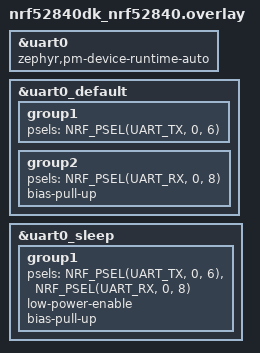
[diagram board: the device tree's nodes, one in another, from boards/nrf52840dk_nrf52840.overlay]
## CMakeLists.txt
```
#
# Copyright (c) 2018 Nordic Semiconductor
#
# SPDX-License-Identifier: LicenseRef-Nordic-5-Clause
#
cmake_minimum_required(VERSION 3.20.0)

# Add configs
list(APPEND EXTRA_CONF_FILE
  "${CMAKE_CURRENT_LIST_DIR}/src/mpsl_esb/mpsl-esb-overlay.conf"
)

set(EXTRA_CONF_FILE ${EXTRA_CONF_FILE} CACHE INTERNAL "")

find_package(Zephyr REQUIRED HINTS $ENV{ZEPHYR_BASE})
project(ble_esb_low_power)

# NORDIC SDK APP START
target_sources(app PRIVATE
  src/main.c
)

add_subdirectory(src/mpsl_esb)

# NORDIC SDK APP END
```

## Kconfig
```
#
# Copyright (c) 2018 Nordic Semiconductor
#
# SPDX-License-Identifier: LicenseRef-Nordic-5-Clause
#

rsource "src/mpsl_esb/Kconfig.mpsl_esb"

source "Kconfig.zephyr"

menu "Nordic LED-Button BLE GATT service sample"

config BT_LBS_SECURITY_ENABLED
	bool "Enable security"
	default y
	select BT_SMP
	select BT_SETTINGS
	select FLASH
	select FLASH_PAGE_LAYOUT
	select FLASH_MAP
	select ZMS if (SOC_FLASH_NRF_RRAM || SOC_FLASH_NRF_MRAM)
	select NVS if !(SOC_FLASH_NRF_RRAM || SOC_FLASH_NRF_MRAM)
	select SETTINGS
	help
	  "Enable BLE security for the LED-Button service"

endmenu
```

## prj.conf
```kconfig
#
# Copyright (c) 2018 Nordic Semiconductor
#
# SPDX-License-Identifier: LicenseRef-Nordic-5-Clause
#
CONFIG_NCS_SAMPLES_DEFAULTS=y

CONFIG_BT=y
CONFIG_BT_PERIPHERAL=y
CONFIG_BT_DEVICE_NAME="Nordic_LBS"

# Enable the LBS service
CONFIG_BT_LBS=y
CONFIG_BT_LBS_POLL_BUTTON=y
CONFIG_DK_LIBRARY=y

CONFIG_BT_MAX_CONN=2

CONFIG_SYSTEM_WORKQUEUE_STACK_SIZE=2048

# ESB
CONFIG_ESB_CLOCK_INIT=n



# CONFIG_DEBUG=y
# CONFIG_THREAD_ANALYZER=y
# CONFIG_THREAD_MONITOR=y
# CONFIG_THREAD_NAME=y
# CONFIG_THREAD_STACK_INFO=y
# CONFIG_THREAD_RUNTIME_STATS=y

# enable logging, set UART as backend
CONFIG_LOG=y
CONFIG_CONSOLE=y
CONFIG_LOG_MODE_DEFERRED=y
CONFIG_LOG_BACKEND_UART=y
CONFIG_PRINTK=y
CONFIG_UART_CONSOLE=y
CONFIG_LOG_PRINTK=y
CONFIG_USE_SEGGER_RTT=n
CONFIG_RTT_CONSOLE=n

# enable async uart for the log backend
CONFIG_LOG_BACKEND_UART_ASYNC=y
CONFIG_UART_ASYNC_API=y


# The hardware counter is only used for RX
# we don't need to use it for logging
# CONFIG_UART_0_NRF_HW_ASYNC=y
# CONFIG_UART_0_NRF_HW_ASYNC_TIMER=1
# CONFIG_NRFX_TIMER1=y


# disable all uart input features
CONFIG_SHELL=n
CONFIG_CONSOLE_HANDLER=n


# Low power for Zephyr Device Drivers
CONFIG_PM_DEVICE_RUNTIME=y
CONFIG_PM_DEVICE=y
```

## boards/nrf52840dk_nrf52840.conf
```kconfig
CONFIG_UART_0_INTERRUPT_DRIVEN=n
CONFIG_UART_0_ASYNC=y
```

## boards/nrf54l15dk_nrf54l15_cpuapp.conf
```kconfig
# nRF54L15: console UART is uart20 (not uart0)
CONFIG_UART_20_INTERRUPT_DRIVEN=n
CONFIG_UART_20_ASYNC=y
```

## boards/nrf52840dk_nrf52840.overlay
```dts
&uart0 {
    status = "okay";
    zephyr,pm-device-runtime-auto;
    /delete-property/ hw-flow-control;
};

&uart0_default {
    group1 {
        psels = <NRF_PSEL(UART_TX, 0, 6)>;
    };
    group2 {
        psels = <NRF_PSEL(UART_RX, 0, 8)>;
        bias-pull-up;
    };
};

&uart0_sleep {
    group1 {
        psels = <NRF_PSEL(UART_TX, 0, 6)>,
            <NRF_PSEL(UART_RX, 0, 8)>;
        low-power-enable;
        bias-pull-up;
    };
};
```

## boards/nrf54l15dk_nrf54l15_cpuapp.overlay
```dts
/* nRF54L15DK: console is on uart20 (TX=P1.4, RX=P1.5) */
&uart20 {
    status = "okay";
    zephyr,pm-device-runtime-auto;
    /delete-property/ hw-flow-control;
};

/* Remove RTS/CTS pins from the default pinctrl group */
&uart20_default {
    group1 {
        psels = <NRF_PSEL(UART_TX, 1, 4)>;
    };
    group2 {
        psels = <NRF_PSEL(UART_RX, 1, 5)>;
        bias-pull-up;
    };
};

&uart20_sleep {
    group1 {
        psels = <NRF_PSEL(UART_TX, 1, 4)>,
            <NRF_PSEL(UART_RX, 1, 5)>;
        low-power-enable;
        bias-pull-up;
    };
};
```

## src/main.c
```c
/*
 * Copyright (c) 2018 Nordic Semiconductor ASA
 *
 * SPDX-License-Identifier: LicenseRef-Nordic-5-Clause
 */

#include <zephyr/types.h>
#include <stddef.h>
#include <string.h>
#include <errno.h>
#include <zephyr/sys/printk.h>
#include <zephyr/sys/byteorder.h>
#include <zephyr/kernel.h>
#include <zephyr/drivers/gpio.h>
#include <soc.h>

#include <zephyr/bluetooth/bluetooth.h>
#include <zephyr/bluetooth/hci.h>
#include <zephyr/bluetooth/conn.h>
#include <zephyr/bluetooth/uuid.h>
#include <zephyr/bluetooth/gatt.h>

#include <bluetooth/services/lbs.h>

#include <zephyr/settings/settings.h>

#include <dk_buttons_and_leds.h>

#define DEVICE_NAME             CONFIG_BT_DEVICE_NAME
#define DEVICE_NAME_LEN         (sizeof(DEVICE_NAME) - 1)


#define RUN_STATUS_LED          DK_LED1
#define CON_STATUS_LED          DK_LED2
#define RUN_LED_BLINK_INTERVAL  1000

#define USER_LED                DK_LED3

#define USER_BUTTON             DK_BTN1_MSK

static bool app_button_state;

static const struct bt_data ad[] = {
	BT_DATA_BYTES(BT_DATA_FLAGS, (BT_LE_AD_GENERAL | BT_LE_AD_NO_BREDR)),
	BT_DATA(BT_DATA_NAME_COMPLETE, DEVICE_NAME, DEVICE_NAME_LEN),
};

static const struct bt_data sd[] = {
	BT_DATA_BYTES(BT_DATA_UUID128_ALL, BT_UUID_LBS_VAL),
};

static void connected(struct bt_conn *conn, uint8_t err)
{
	if (err) {
		printk("Connection failed, err 0x%02x %s\n", err, bt_hci_err_to_str(err));
		return;
	}

	printk("Connected\n");

	dk_set_led_on(CON_STATUS_LED);

	struct bt_le_conn_param param = {
		.interval_min = 400, // 400 * 1.25 ms = 500 ms
		.interval_max = 400, // 400 * 1.25 ms = 500 ms
		.latency = 0,       
		.timeout = 200,     // 200*10ms = 2s
        /**
         * Bluetooth requries:
         *   Timeout_ms > 2 * (1 + latency_ms) * interval_max_ms
         * 
		 * variable style:
         *   timeout * 4 > (1 + latency) * interval_max
         */
        /**
         * iOS Requriements:
         *   - Interval Min ≥ 15 ms (multiples of 15 ms)
         *   - Interval Min + 15 ms ≤ Interval Max (Interval Max == 15 ms is allowed)
         *   - Interval Max * (Slave Latency + 1) ≤ 2 seconds
         *   - Interval Max * (Slave Latency + 1) * 3 < connSupervisionTimeout
         *   - Slave Latency ≤ 30
         *   - 2 seconds ≤ connSupervisionTimeout ≤ 6 seconds
         */

	};

	int ret = bt_conn_le_param_update(conn, &param);

	if (ret == -EALREADY) {
        printk("Connection parameters are already set.");
		ret = 0;
	}
    
    if (ret) {
        printk("Failed to update connection parameters (ret %d)", ret);
    }
}

static void disconnected(struct bt_conn *conn, uint8_t reason)
{
	printk("Disconnected, reason 0x%02x %s\n", reason, bt_hci_err_to_str(reason));

	dk_set_led_off(CON_STATUS_LED);
}

#ifdef CONFIG_BT_LBS_SECURITY_ENABLED
static void security_changed(struct bt_conn *conn, bt_security_t level,
			     enum bt_security_err err)
{
	char addr[BT_ADDR_LE_STR_LEN];

	bt_addr_le_to_str(bt_conn_get_dst(conn), addr, sizeof(addr));

	if (!err) {
		printk("Security changed: %s level %u\n", addr, level);
	} else {
		printk("Security failed: %s level %u err %d %s\n", addr, level, err,
		       bt_security_err_to_str(err));
	}
}
#endif

BT_CONN_CB_DEFINE(conn_callbacks) = {
	.connected        = connected,
	.disconnected     = disconnected,
#ifdef CONFIG_BT_LBS_SECURITY_ENABLED
	.security_changed = security_changed,
#endif
};

#if defined(CONFIG_BT_LBS_SECURITY_ENABLED)
static void auth_passkey_display(struct bt_conn *conn, unsigned int passkey)
{
	char addr[BT_ADDR_LE_STR_LEN];

	bt_addr_le_to_str(bt_conn_get_dst(conn), addr, sizeof(addr));

	printk("Passkey for %s: %06u\n", addr, passkey);
}

static void auth_cancel(struct bt_conn *conn)
{
	char addr[BT_ADDR_LE_STR_LEN];

	bt_addr_le_to_str(bt_conn_get_dst(conn), addr, sizeof(addr));

	printk("Pairing cancelled: %s\n", addr);
}

static void pairing_complete(struct bt_conn *conn, bool bonded)
{
	char addr[BT_ADDR_LE_STR_LEN];

	bt_addr_le_to_str(bt_conn_get_dst(conn), addr, sizeof(addr));

	printk("Pairing completed: %s, bonded: %d\n", addr, bonded);
}

static void pairing_failed(struct bt_conn *conn, enum bt_security_err reason)
{
	char addr[BT_ADDR_LE_STR_LEN];

	bt_addr_le_to_str(bt_conn_get_dst(conn), addr, sizeof(addr));

	printk("Pairing failed conn: %s, reason %d %s\n", addr, reason,
	       bt_security_err_to_str(reason));
}

static struct bt_conn_auth_cb conn_auth_callbacks = {
	.passkey_display = auth_passkey_display,
	.cancel = auth_cancel,
};

static struct bt_conn_auth_info_cb conn_auth_info_callbacks = {
	.pairing_complete = pairing_complete,
	.pairing_failed = pairing_failed
};
#else
static struct bt_conn_auth_cb conn_auth_callbacks;
static struct bt_conn_auth_info_cb conn_auth_info_callbacks;
#endif

static void app_led_cb(bool led_state)
{
	dk_set_led(USER_LED, led_state);
}

static bool app_button_cb(void)
{
	return app_button_state;
}

static struct bt_lbs_cb lbs_callbacs = {
	.led_cb    = app_led_cb,
	.button_cb = app_button_cb,
};

static void button_changed(uint32_t button_state, uint32_t has_changed)
{
	if (has_changed & USER_BUTTON) {
		uint32_t user_button_state = button_state & USER_BUTTON;

		bt_lbs_send_button_state(user_button_state);
		app_button_state = user_button_state ? true : false;
	}
}

static int init_button(void)
{
	int err;

	err = dk_buttons_init(button_changed);
	if (err) {
		printk("Cannot init buttons (err: %d)\n", err);
	}

	return err;
}

int main(void)
{
	int blink_status = 0;
	int err;

	printk("Starting Bluetooth Peripheral LBS example\n");

	err = dk_leds_init();
	if (err) {
		printk("LEDs init failed (err %d)\n", err);
		return 0;
	}

	err = init_button();
	if (err) {
		printk("Button init failed (err %d)\n", err);
		return 0;
	}

	if (IS_ENABLED(CONFIG_BT_LBS_SECURITY_ENABLED)) {
		err = bt_conn_auth_cb_register(&conn_auth_callbacks);
		if (err) {
			printk("Failed to register authorization callbacks.\n");
			return 0;
		}

		err = bt_conn_auth_info_cb_register(&conn_auth_info_callbacks);
		if (err) {
			printk("Failed to register authorization info callbacks.\n");
			return 0;
		}
	}

	err = bt_enable(NULL);
	if (err) {
		printk("Bluetooth init failed (err %d)\n", err);
		return 0;
	}

	printk("Bluetooth initialized\n");

	if (IS_ENABLED(CONFIG_SETTINGS)) {
		settings_load();
	}

	err = bt_lbs_init(&lbs_callbacs);
	if (err) {
		printk("Failed to init LBS (err:%d)\n", err);
		return 0;
	}

    struct bt_le_adv_param adv_param = {
        .options = BT_LE_ADV_OPT_CONN,
        .interval_min = 800, // 800 * 0.625 ms = 500 ms
        .interval_max = 800, // 800 * 0.625 ms = 500 ms
        .peer = NULL,
    };

	err = bt_le_adv_start(&adv_param, ad, ARRAY_SIZE(ad),
			      sd, ARRAY_SIZE(sd));
	if (err) {
		printk("Advertising failed to start (err %d)\n", err);
		return 0;
	}

	printk("Advertising successfully started\n");

	for (;;) {
		dk_set_led(RUN_STATUS_LED, (++blink_status) % 2);
		k_sleep(K_MSEC(RUN_LED_BLINK_INTERVAL));
	}
}
```
